# STM32U5G9 register map
File version: 1.3
CPU: CM33 r0p1, little endian, MPU, FPU, 4 interrupt priority bits
Registers are 32-bit, read-write, reset 0x0 unless marked. A register's access mark holds for its fields unless they carry their own. Offsets are from the block's base; [hi:lo] are bit positions; 'fields as' and 'values as' point back to an identical list.

## OCTOSPIM — OCTOSPI I/O manager
Base 0x420C4000
Same registers: SEC_OCTOSPIM 0x520C4000
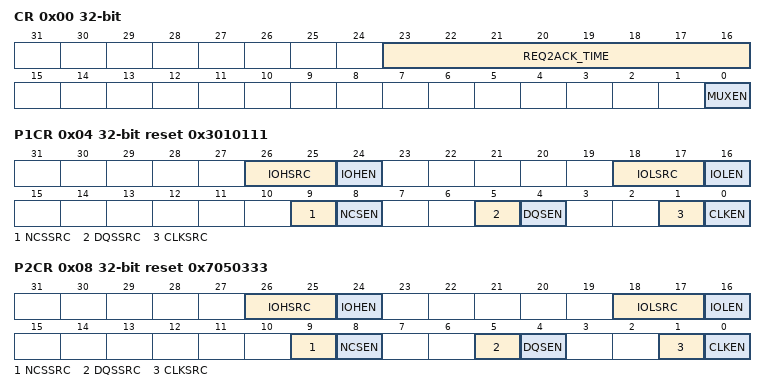
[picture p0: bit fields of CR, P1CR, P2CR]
0x00 CR — control register
  [23:16] REQ2ACK_TIME — REQ to ACK time
  [0] MUXEN — Multiplexed mode enable
0x04 P1CR reset 0x3010111 — OCTOSPI I/O manager Port 1 configuration register
  [26:25] IOHSRC — IOHSR
  [24] IOHEN
  [18:17] IOLSRC
  [16] IOLEN
  [9] NCSSRC
  [8] NCSEN
  [5] DQSSRC
  [4] DQSEN
  [1] CLKSRC
  [0] CLKEN
0x08 P2CR reset 0x7050333 — OCTOSPI I/O manager Port 2 configuration register
  fields as P1CR

## OPAMP — Operational amplifiers
Base 0x46005000
Same registers: SEC_OPAMP 0x56005000
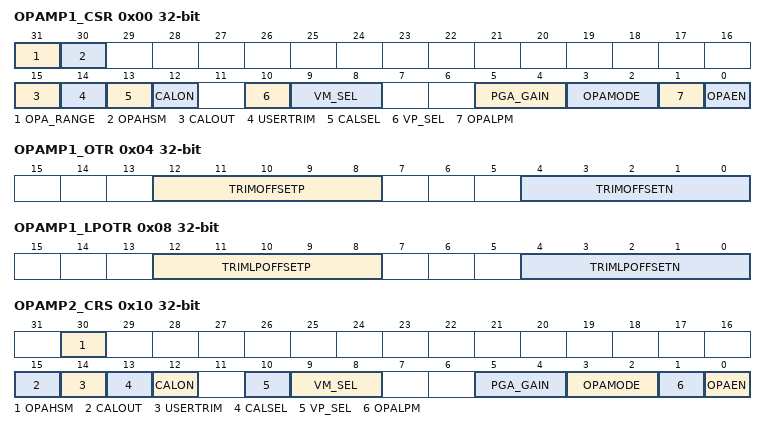
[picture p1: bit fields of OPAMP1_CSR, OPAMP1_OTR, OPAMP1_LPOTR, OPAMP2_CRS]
0x00 OPAMP1_CSR access per field — OPAMP1 control/status register
  [31] OPA_RANGE rw — OPAMP range setting
    1=OPAMP range set
  [30] OPAHSM rw — OPAMP high-speed mode
    0=normal mode (standard slew rate); 1=increased consumption to improve the slew rate
  [15] CALOUT ro — OPAMP calibration output
  [14] USERTRIM rw — factory' or user' offset trimmed values selection
    0=factory' trim code used; 1=user' trim code used
  [13] CALSEL rw — Calibration selection
    0=NMOS calibration (200 mV applied on OPAMP inputs); 1=PMOS calibration (Vless thansub>DDA less than/sub>- 200 mV applied on OPAMP inputs)
  [12] CALON rw — Calibration mode enable
    0=normal mode; 1=calibration mode (all switches opened by hardware)
  [10] VP_SEL rw — Non-inverted input selection
    0=GPIO connected to VINP; 1=DAC connected to VINP
  [9:8] VM_SEL rw — Inverting input selection
    0=GPIO connected to VINM (valid also in PGA mode for filtering); 1=dedicated low-leakage input connected to VINM (valid also in PGA mode for filtering)
  [5:4] PGA_GAIN rw — OPAMP programmable amplifier gain value
    0=internal PGA gain 2; 1=internal PGA gain 4; 2=internal PGA gain 8; 3=internal PGA gain 16
  [3:2] OPAMODE rw — OPAMP PGA mode
    2=internal PGA enabled, gain programmed in PGA_GAIN; 3=internal follower
  [1] OPALPM rw — OPAMP low-power mode
    0=normal mode; 1=low-power mode
  [0] OPAEN rw — OPAMP enable
    0=OPAMP disabled; 1=OPAMP enabled
0x04 OPAMP1_OTR (reset mask 0xFFFF0000) — OPAMP1 offset trimming register in normal mode
  [12:8] TRIMOFFSETP — Trim for PMOS differential pairs
  [4:0] TRIMOFFSETN — Trim for NMOS differential pairs
0x08 OPAMP1_LPOTR (reset mask 0xFFFF0000) — OPAMP1 offset trimming register in low-power mode
  [12:8] TRIMLPOFFSETP — Low-power mode trim for PMOS differential pairs
  [4:0] TRIMLPOFFSETN — Low-power mode trim for NMOS differential pairs
0x10 OPAMP2_CRS access per field — OPAMP2 control/status register
  [30] OPAHSM rw — OPAMP high-speed mode
    values as OPAMP1_CSR.OPAHSM
  [15] CALOUT ro — OPAMP calibration output
  [14] USERTRIM rw — factory' or user' offset trimmed values selection
    0=factory' trim code used; 1=user' trim code used
  [13] CALSEL rw — Calibration selection
    values as OPAMP1_CSR.CALSEL
  [12] CALON rw — Calibration mode enable
    values as OPAMP1_CSR.CALON
  [10] VP_SEL rw — Non inverted input selection
    0=GPIO connected to VINP; 1=DAC connected to VINP
  [9:8] VM_SEL rw — Inverting input selection
    0=GPIO connected to VINM (valid also in PGA mode for filtering); 1=dedicated low-leakage input connected to VINM (valid also
  [5:4] PGA_GAIN rw — OPAMP programmable amplifier gain value
    values as OPAMP1_CSR.PGA_GAIN
  [3:2] OPAMODE rw — OPAMP PGA mode
    values as OPAMP1_CSR.OPAMODE
  [1] OPALPM rw — OPAMP low-power mode
    0=normal mode; 1=low-power mode
  [0] OPAEN rw — OPAMP enable
    0=OPAMP disabled; 1=OPAMP enabled
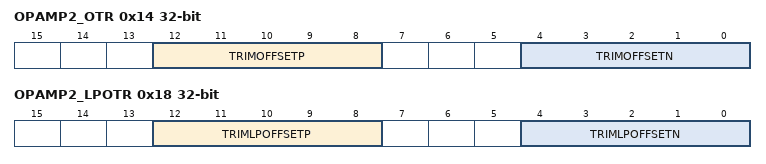
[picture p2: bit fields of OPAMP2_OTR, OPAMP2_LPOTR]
0x14 OPAMP2_OTR (reset mask 0xFFFF0000) — OPAMP2 offset trimming register in normal mode
  fields as OPAMP1_OTR
0x18 OPAMP2_LPOTR (reset mask 0xFFFF0000) — OPAMP2 offset trimming register in low-power mode
  fields as OPAMP1_LPOTR
